# SIMG301M114KIH register map
Vendor: Silicon Labs; Series: Si; File version: B
Registers are 32-bit, read-write, reset 0x0 unless marked. A register's access mark holds for its fields unless they carry their own. Offsets are from the block's base; [hi:lo] are bit positions; {n}, {i} and the like mark numbered series.

## SMU_NS_CFGNS — SMU_NS_CFGNS Registers
Base 0x4100C000
Same registers: SMU_S_CFGNS 0x5100C000
0x04 NSSTATUS ro
  [0] SMUNSLOCK
    0=UNLOCKED; 1=LOCKED
0x08 NSLOCK wo
  [23:0] SMUNSLOCKKEY
    0xACCE55=UNLOCK (Unlocks Registers)
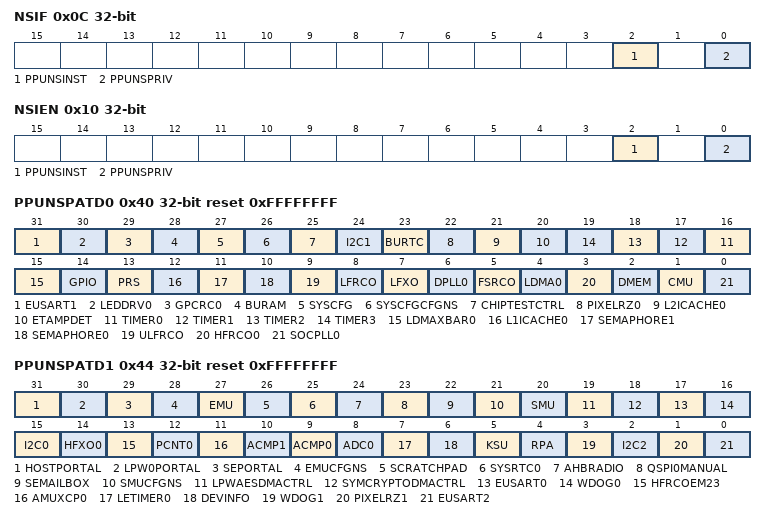
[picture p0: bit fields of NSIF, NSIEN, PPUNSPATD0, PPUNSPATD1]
0x0C NSIF
  [2] PPUNSINST — PPUNS Instruction Interrupt Flag
  [0] PPUNSPRIV — PPUNS Privilege Interrupt Flag
0x10 NSIEN
  [2] PPUNSINST — PPUNS Instruction Interrupt Enable
  [0] PPUNSPRIV — PPUNS Privilege Interrupt Enable
0x40 PPUNSPATD0 reset 0xFFFFFFFF — Set peripheral bits to 1 to mark as privileged access only
  [31] EUSART1 — EUSART1 Privileged Access
  [30] LEDDRV0 — LEDDRV0 Privileged Access
  [29] GPCRC0 — GPCRC0 Privileged Access
  [28] BURAM — BURAM Privileged Access
  [27] SYSCFG — SYSCFG Privileged Access
  [26] SYSCFGCFGNS — SYSCFGCFGNS Privileged Access
  [25] CHIPTESTCTRL — CHIPTESTCTRL Privileged Access
  [24] I2C1 — I2C1 Privileged Access
  [23] BURTC — BURTC Privileged Access
  [22] PIXELRZ0 — PIXELRZ0 Privileged Access
  [21] L2ICACHE0 — L2ICACHE0 Privileged Access
  [20] ETAMPDET — ETAMPDET Privileged Access
  [n+16] TIMER{n} (n=0..3) — TIMER{n} Privileged Access
  [15] LDMAXBAR0 — LDMAXBAR0 Privileged Access
  [14] GPIO — GPIO Privileged Access
  [13] PRS — PRS Privileged Access
  [12] L1ICACHE0 — L1ICACHE0 Privileged Access
  [11] SEMAPHORE1 — SEMAPHORE1 Privileged Access
  [10] SEMAPHORE0 — SEMAPHORE0 Privileged Access
  [9] ULFRCO — ULFRCO Privileged Access
  [8] LFRCO — LFRCO Privileged Access
  [7] LFXO — LFXO Privileged Access
  [6] DPLL0 — DPLL0 Privileged Access
  [5] FSRCO — FSRCO Privileged Access
  [4] LDMA0 — LDMA0 Privileged Access
  [3] HFRCO0 — HFRCO0 Privileged Access
  [2] DMEM — DMEM Privileged Access
  [1] CMU — CMU Privileged Access
  [0] SOCPLL0 — SOCPLL0 Privileged Access
0x44 PPUNSPATD1 reset 0xFFFFFFFF — Set peripheral bits to 1 to mark as privileged access only
  [31] HOSTPORTAL — HOSTPORTAL Privileged Access
  [30] LPW0PORTAL — LPW0PORTAL Privileged Access
  [29] SEPORTAL — SEPORTAL Privileged Access
  [28] EMUCFGNS — EMUCFGNS Privileged Access
  [27] EMU — EMU Privileged Access
  [26] SCRATCHPAD — SCRATCHPAD Privileged Access
  [25] SYSRTC0 — SYSRTC0 Privileged Access
  [24] AHBRADIO — AHBRADIO Privileged Access
  [23] QSPI0MANUAL — QSPI0MANUAL Privileged Access
  [22] SEMAILBOX — SEMAILBOX Privileged Access
  [21] SMUCFGNS — SMUCFGNS Privileged Access
  [20] SMU — SMU Privileged Access
  [19] LPWAESDMACTRL — LPWAESDMACTRL Privileged Access
  [18] SYMCRYPTODMACTRL — SYMCRYPTODMACTRL Privileged Access
  [17] EUSART0 — EUSART0 Privileged Access
  [16] WDOG0 — WDOG0 Privileged Access
  [15] I2C0 — I2C0 Privileged Access
  [14] HFXO0 — HFXO0 Privileged Access
  [13] HFRCOEM23 — HFRCOEM23 Privileged Access
  [12] PCNT0 — PCNT0 Privileged Access
  [11] AMUXCP0 — AMUXCP0 Privileged Access
  [10] ACMP1 — ACMP1 Privileged Access
  [9] ACMP0 — ACMP0 Privileged Access
  [8] ADC0 — ADC0 Privileged Access
  [7] LETIMER0 — LETIMER0 Privileged Access
  [6] DEVINFO — DEVINFO Privileged Access
  [5] KSU — KSU Privileged Access
  [4] RPA — RPA Privileged Access
  [3] WDOG1 — WDOG1 Privileged Access
  [2] I2C2 — I2C2 Privileged Access
  [1] PIXELRZ1 — PIXELRZ1 Privileged Access
  [0] EUSART2 — EUSART2 Privileged Access
0x140 PPUNSFS ro
  [7:0] PPUFSPERIPHID — Peripheral I
0x144 PPUNSFSADDR ro
  [31:0] PPUFSADDR — Fault Address
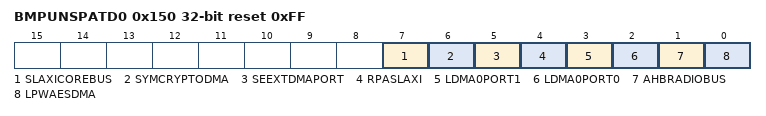
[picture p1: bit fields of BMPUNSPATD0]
0x150 BMPUNSPATD0 reset 0xFF
  [7] SLAXICOREBUS — SLAXICOREBUS Privileged Mode
  [6] SYMCRYPTODMA — SYMCRYPTODMA Privileged Mode
  [5] SEEXTDMAPORT — SEEXTDMAPORT Privileged Mode
  [4] RPASLAXI — RPASLAXI Privileged Mode
  [3] LDMA0PORT1 — LDMA0PORT1 Privileged Mode
  [2] LDMA0PORT0 — LDMA0PORT0 Privileged Mode
  [1] AHBRADIOBUS — AHBRADIOBUS Privileged Mode
  [0] LPWAESDMA — LPWAESDMA Privileged Mode
